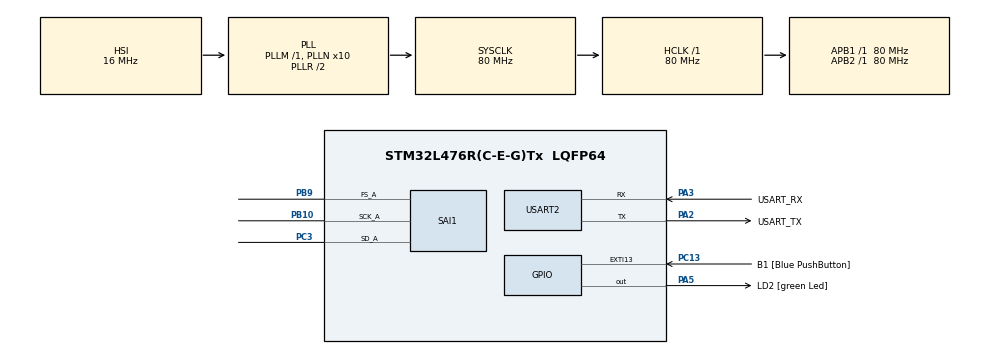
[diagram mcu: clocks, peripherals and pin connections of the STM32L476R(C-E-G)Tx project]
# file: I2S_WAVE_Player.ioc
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Mcu.Family=STM32L4
PC3.Mode=SAI_A_Master
PA2.GPIO_PuPd=GPIO_NOPULL
RCC.CortexFreq_Value=80000000
PB10.Mode=SAI_A_Master
PH0-OSC_IN\ (PH0).Signal=RCC_OSC_IN
PA3.GPIO_PuPd=GPIO_NOPULL
SAI1.VirtualProtocol-SAI_A_BASIC=VM_BASIC_PROTOCOL
PA2.GPIO_Speed=GPIO_SPEED_FREQ_VERY_HIGH
PC15-OSC32_OUT\ (PC15).Mode=LSE-External-Oscillator
PC13.GPIO_Label=B1 [Blue PushButton]
PA3.GPIO_Speed=GPIO_SPEED_FREQ_VERY_HIGH
SAI1.Instance-SAI_A_Master=SAI$Index_Block_A
RCC.SYSCLKSource=RCC_SYSCLKSOURCE_PLLCLK
ProjectManager.StackSize=0x400
PB3\ (JTDO-TRACESWO).Signal=SYS_JTDO-SWO
PC14-OSC32_IN\ (PC14).Mode=LSE-External-Oscillator
PA14\ (JTCK-SWCLK).Signal=SYS_JTCK-SWCLK
RCC.HCLKFreq_Value=80000000
RCC.APB2TimFreq_Value=80000000
PC3.Signal=SAI1_SD_A
RCC.AHBFreq_Value=80000000
RCC.PREFETCH_ENABLE=1
RCC.HSE_VALUE=8000000
USART2.VirtualMode-Asynchronous=VM_ASYNC
PA5.GPIO_PuPd=GPIO_NOPULL
PC13.GPIO_PuPd=GPIO_NOPULL
Mcu.Package=LQFP64
PB9.Signal=SAI1_FS_A
Dma.SAI1_A.0.MemDataAlignment=DMA_MDATAALIGN_HALFWORD
PA2.GPIO_Label=USART_TX
SAI1.VirtualMode-SAI_A_Master=VM_MASTER
RCC.APB1TimFreq_Value=80000000
PA13\ (JTMS-SWDIO).Signal=SYS_JTMS-SWDIO
SAI1.MonoStereoMode-SAI_A_Master=SAI_MONOMODE
Dma.Request0=SAI1_A
RCC.PLLSAI1P=RCC_PLLP_DIV17
RCC.PLLSAI1N=12
PA3.Signal=USART2_RX
PA2.GPIO_Mode=GPIO_MODE_AF_PP
RCC.MSI_VALUE=4000000
RCC.PLLSourceVirtual=RCC_PLLSOURCE_HSI
PA14\ (JTCK-SWCLK).Mode=Serial_Wire
VP_SAI1_VP_$IpInstance_SAIA_SAI_BASIC.Mode=SAI_A_BASIC
Dma.SAI1_A.0.Direction=DMA_MEMORY_TO_PERIPH
PC13.Signal=GPXTI13
SAI1.NoDivider-SAI_A_Master=SAI_MASTERDIVIDER_ENABLE
PC15-OSC32_OUT\ (PC15).Signal=RCC_OSC32_OUT
PA14\ (JTCK-SWCLK).GPIO_Label=TCK
PB3\ (JTDO-TRACESWO).GPIO_Label=SWO
Dma.SAI1_A.0.MemInc=DMA_MINC_ENABLE
SAI1.MClockEnable-SAI_A_Master=SAI_MASTERCLOCK_DISABLE
PH1-OSC_OUT\ (PH1).Signal=RCC_OSC_OUT
SAI1.RealAudioFreq-SAI_A_Master=44.117 KHz
PA3.Mode=Asynchronous
ProjectManager.TargetToolchain=STM32CubeIDE
Dma.SAI1_A.0.Mode=DMA_NORMAL
SAI1.ErrorAudioFreq-SAI_A_Master=0.26 %
PA3.GPIO_Mode=GPIO_MODE_AF_PP
PB9.Mode=SAI_A_Master
RCC.USBFreq_Value=96000000
SAI1.AudioFrequency-SAI_A_Master=SAI_AUDIO_FREQUENCY_44K
PB10.Signal=SAI1_SCK_A
Dma.SAI1_A.0.Priority=DMA_PRIORITY_LOW
PA5.Signal=GPIO_Output
board=NUCLEO-L476RG
RCC.VCOOutputFreq_Value=160000000
Dma.SAI1_A.0.PeriphInc=DMA_PINC_DISABLE
RCC.APB2Freq_Value=80000000
PA5.GPIO_ModeDefaultOutputPP=GPIO_MODE_OUTPUT_PP
PA13\ (JTMS-SWDIO).GPIO_Label=TMS
RCC.ADCFreq_Value=96000000
Mcu.Name=STM32L476R(C-E-G)Tx
PA2.Signal=USART2_TX
PA13\ (JTMS-SWDIO).Mode=Serial_Wire
RCC.SYSCLKFreq_VALUE=80000000
PA5.GPIO_Label=LD2 [green Led]
PC13.GPIO_ModeDefaultEXTI=GPIO_MODE_IT_FALLING
PC14-OSC32_IN\ (PC14).Signal=RCC_OSC32_IN
NVIC.DMA2_Channel1_IRQn=true\:0\:0\:false\:false\:true\:false\:true
ProjectManager.HeapSize=0x200
RCC.HSI_VALUE=16000000
PA5.GPIO_Speed=GPIO_SPEED_FREQ_LOW
NVIC.PriorityGroup=NVIC_PRIORITYGROUP_4
RCC.PLLN=10
PA2.Mode=Asynchronous
RCC.APB1Freq_Value=80000000
Dma.SAI1_A.0.Instance=DMA2_Channel1
Dma.SAI1_A.0.PeriphDataAlignment=DMA_PDATAALIGN_HALFWORD
SAI1.InitProtocol-SAI_A_Master=Enable
PA3.GPIO_Label=USART_RX

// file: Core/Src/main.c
/* USER CODE BEGIN Header */
/**
  ******************************************************************************
  * @file           : main.c
  * @brief          : Main program body
  ******************************************************************************
  * @attention
  *
  * <h2><center>&copy; Copyright (c) 2021 STMicroelectronics.
  * All rights reserved.</center></h2>
  *
  * This software component is licensed by ST under BSD 3-Clause license,
  * the "License"; You may not use this file except in compliance with the
  * License. You may obtain a copy of the License at:
  *                        opensource.org/licenses/BSD-3-Clause
  *
  ******************************************************************************
  */
/* USER CODE END Header */
#include "main.h"
#include "dma.h"
#include "sai.h"
#include "usart.h"
#include "gpio.h"

/* USER CODE BEGIN PV */
extern uint8_t audio_file[];
/* USER CODE END PV */

void SystemClock_Config(void);

int main(void)
{

  /* MCU Configuration--------------------------------------------------------*/

  /* Reset of all peripherals, Initializes the Flash interface and the Systick. */
  HAL_Init();

  /* Configure the system clock */
  SystemClock_Config();

  /* Initialize all configured peripherals */
  MX_GPIO_Init();
  MX_DMA_Init();
  MX_USART2_UART_Init();
  MX_SAI1_Init();
  /* USER CODE BEGIN 2 */
  wave_player_init(&hsai_BlockA1);
  wave_player_start(audio_file);
  /* USER CODE END 2 */

  /* Infinite loop */
  while (1)
  {

  }
}

void SystemClock_Config(void)
{
  RCC_OscInitTypeDef RCC_OscInitStruct = {0};
  RCC_ClkInitTypeDef RCC_ClkInitStruct = {0};
  RCC_PeriphCLKInitTypeDef PeriphClkInit = {0};

  /** Initializes the RCC Oscillators according to the specified parameters
  * in the RCC_OscInitTypeDef structure.
  */
  RCC_OscInitStruct.OscillatorType = RCC_OSCILLATORTYPE_HSI;
  RCC_OscInitStruct.HSIState = RCC_HSI_ON;
  RCC_OscInitStruct.HSICalibrationValue = RCC_HSICALIBRATION_DEFAULT;
  RCC_OscInitStruct.PLL.PLLState = RCC_PLL_ON;
  RCC_OscInitStruct.PLL.PLLSource = RCC_PLLSOURCE_HSI;
  RCC_OscInitStruct.PLL.PLLM = 1;
  RCC_OscInitStruct.PLL.PLLN = 10;
  RCC_OscInitStruct.PLL.PLLP = RCC_PLLP_DIV7;
  RCC_OscInitStruct.PLL.PLLQ = RCC_PLLQ_DIV2;
  RCC_OscInitStruct.PLL.PLLR = RCC_PLLR_DIV2;
  if (HAL_RCC_OscConfig(&RCC_OscInitStruct) != HAL_OK)
  {
    Error_Handler();
  }
  /** Initializes the CPU, AHB and APB buses clocks
  */
  RCC_ClkInitStruct.ClockType = RCC_CLOCKTYPE_HCLK|RCC_CLOCKTYPE_SYSCLK
                              |RCC_CLOCKTYPE_PCLK1|RCC_CLOCKTYPE_PCLK2;
  RCC_ClkInitStruct.SYSCLKSource = RCC_SYSCLKSOURCE_PLLCLK;
  RCC_ClkInitStruct.AHBCLKDivider = RCC_SYSCLK_DIV1;
  RCC_ClkInitStruct.APB1CLKDivider = RCC_HCLK_DIV1;
  RCC_ClkInitStruct.APB2CLKDivider = RCC_HCLK_DIV1;

  if (HAL_RCC_ClockConfig(&RCC_ClkInitStruct, FLASH_LATENCY_4) != HAL_OK)
  {
    Error_Handler();
  }
  PeriphClkInit.PeriphClockSelection = RCC_PERIPHCLK_USART2|RCC_PERIPHCLK_SAI1;
  PeriphClkInit.Usart2ClockSelection = RCC_USART2CLKSOURCE_PCLK1;
  PeriphClkInit.Sai1ClockSelection = RCC_SAI1CLKSOURCE_PLLSAI1;
  PeriphClkInit.PLLSAI1.PLLSAI1Source = RCC_PLLSOURCE_HSI;
  PeriphClkInit.PLLSAI1.PLLSAI1M = 1;
  PeriphClkInit.PLLSAI1.PLLSAI1N = 12;
  PeriphClkInit.PLLSAI1.PLLSAI1P = RCC_PLLP_DIV17;
  PeriphClkInit.PLLSAI1.PLLSAI1Q = RCC_PLLQ_DIV2;
  PeriphClkInit.PLLSAI1.PLLSAI1R = RCC_PLLR_DIV2;
  PeriphClkInit.PLLSAI1.PLLSAI1ClockOut = RCC_PLLSAI1_SAI1CLK;
  if (HAL_RCCEx_PeriphCLKConfig(&PeriphClkInit) != HAL_OK)
  {
    Error_Handler();
  }
  /** Configure the main internal regulator output voltage
  */
  if (HAL_PWREx_ControlVoltageScaling(PWR_REGULATOR_VOLTAGE_SCALE1) != HAL_OK)
  {
    Error_Handler();
  }
}

/* USER CODE BEGIN 4 */
void HAL_SAI_TxCpltCallback(SAI_HandleTypeDef *hsai)
{
	wave_player_prepare_half_buffer(SECOND_HALF_OF_BUFFER);
}

void HAL_SAI_TxHalfCpltCallback(SAI_HandleTypeDef *hsai)
{
	wave_player_prepare_half_buffer(FIRST_HALF_OF_BUFFER);
}
/* USER CODE END 4 */

void Error_Handler(void)
{
  __disable_irq();
  while (1)
  {
  }
}

/************************ (C) COPYRIGHT STMicroelectronics *****END OF FILE****/
